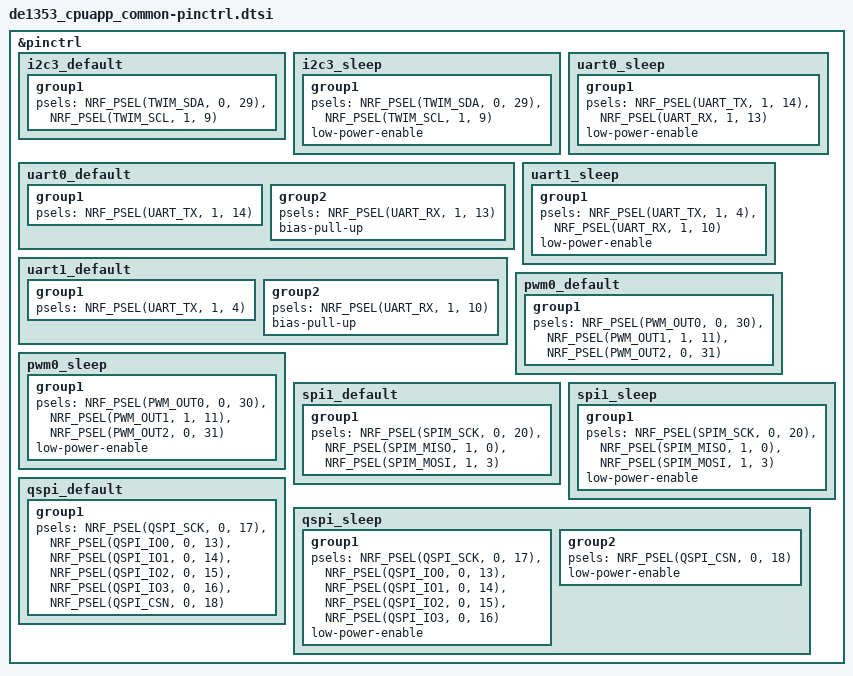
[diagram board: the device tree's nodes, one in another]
/*
 * Copyright (c) 2022 Nordic Semiconductor
 * SPDX-License-Identifier: Apache-2.0
 */

&pinctrl {
	i2c3_default: i2c3_default {
		group1 {
			psels = <NRF_PSEL(TWIM_SDA, 0, 29)>,
				<NRF_PSEL(TWIM_SCL, 1, 9)>;
		};
	};

	i2c3_sleep: i2c3_sleep {
		group1 {
			psels = <NRF_PSEL(TWIM_SDA, 0, 29)>,
				<NRF_PSEL(TWIM_SCL, 1, 9)>;
			low-power-enable;
		};
	};

	uart0_default: uart0_default {
		group1 {
			psels = <NRF_PSEL(UART_TX, 1, 14)>;
		};
		group2 {
			psels = <NRF_PSEL(UART_RX, 1, 13)>;
			bias-pull-up;
		};
	};

	uart0_sleep: uart0_sleep {
		group1 {
			psels = <NRF_PSEL(UART_TX, 1, 14)>,
				<NRF_PSEL(UART_RX, 1, 13)>;
			low-power-enable;
		};
	};

	uart1_default: uart1_default {
		group1 {
			psels = <NRF_PSEL(UART_TX, 1, 4)>;
		};
		group2 {
			psels = <NRF_PSEL(UART_RX, 1, 10)>;
			bias-pull-up;
		};
	};

	uart1_sleep: uart1_sleep {
		group1 {
			psels = <NRF_PSEL(UART_TX, 1, 4)>,
				<NRF_PSEL(UART_RX, 1, 10)>;
			low-power-enable;
		};
	};

	pwm0_default: pwm0_default {
		group1 {
			psels = <NRF_PSEL(PWM_OUT0, 0, 30)>, <NRF_PSEL(PWM_OUT1, 1, 11)>, <NRF_PSEL(PWM_OUT2, 0, 31)>;
		};
	};

	pwm0_sleep: pwm0_sleep {
		group1 {
			psels = <NRF_PSEL(PWM_OUT0, 0, 30)>, <NRF_PSEL(PWM_OUT1, 1, 11)>, <NRF_PSEL(PWM_OUT2, 0, 31)>;
			low-power-enable;
		};
	};

	spi1_default: spi1_default {
		group1 {
			psels = <NRF_PSEL(SPIM_SCK, 0, 20)>,
				<NRF_PSEL(SPIM_MISO, 1, 0)>,
				<NRF_PSEL(SPIM_MOSI, 1, 3)>;
		};
	};

	spi1_sleep: spi1_sleep {
		group1 {
			psels = <NRF_PSEL(SPIM_SCK, 0, 20)>,
				<NRF_PSEL(SPIM_MISO, 1, 0)>,
				<NRF_PSEL(SPIM_MOSI, 1, 3)>;
			low-power-enable;
		};
	};

	qspi_default: qspi_default {
		group1 {
			psels = <NRF_PSEL(QSPI_SCK, 0, 17)>,
				<NRF_PSEL(QSPI_IO0, 0, 13)>,
				<NRF_PSEL(QSPI_IO1, 0, 14)>,
				<NRF_PSEL(QSPI_IO2, 0, 15)>,
				<NRF_PSEL(QSPI_IO3, 0, 16)>,
				<NRF_PSEL(QSPI_CSN, 0, 18)>;
		};
	};

	qspi_sleep: qspi_sleep {
		group1 {
			psels = <NRF_PSEL(QSPI_SCK, 0, 17)>,
				<NRF_PSEL(QSPI_IO0, 0, 13)>,
				<NRF_PSEL(QSPI_IO1, 0, 14)>,
				<NRF_PSEL(QSPI_IO2, 0, 15)>,
				<NRF_PSEL(QSPI_IO3, 0, 16)>;
			low-power-enable;
		};
		group2 {
			psels = <NRF_PSEL(QSPI_CSN, 0, 18)>;
			low-power-enable;
		};
	};

};
